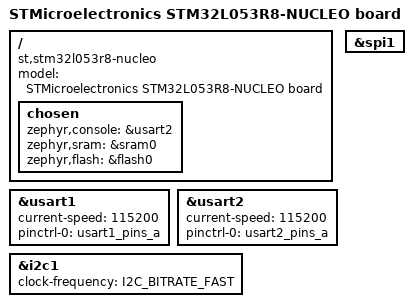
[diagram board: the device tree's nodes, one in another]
/*
 * Copyright (c) 2018 Ilya Tagunov <tagunil@gmail.com>
 * Copyright (c) 2018 Tuomas Kulve <tuomas@kulve.fi>
 *
 * SPDX-License-Identifier: Apache-2.0
 */

/dts-v1/;
#include <st/stm32l053.dtsi>

/ {
	model = "STMicroelectronics STM32L053R8-NUCLEO board";
	compatible = "st,stm32l053r8-nucleo", "st,stm32l053";

	chosen {
		zephyr,console = &usart2;
		zephyr,sram = &sram0;
		zephyr,flash = &flash0;
	};
};

&usart1 {
	current-speed = <115200>;
	pinctrl-0 = <&usart1_pins_a>;
	pinctrl-names = "default";
};

&usart2 {
	current-speed = <115200>;
	pinctrl-0 = <&usart2_pins_a>;
	pinctrl-names = "default";
	status = "ok";
};

&i2c1 {
	status = "ok";
	clock-frequency = <I2C_BITRATE_FAST>;
};

&spi1 {
	status = "ok";
};
